# nrf7120_enga_application register map
Vendor: Nordic Semiconductor; Series: nrf71; File version: 1
CPU: CM33 r0p4, little endian, MPU, FPU, 3 interrupt priority bits, 270 interrupts, 4 SAU regions
Registers are 32-bit, read-write, reset 0x0 unless marked. A register's access mark holds for its fields unless they carry their own. Offsets are from the block's base; [hi:lo] are bit positions; {n}, {i} and the like mark numbered series; 'fields as' and 'values as' point back to an identical list; <NAME> marks a mode.

## GLOBAL_COMP_NS — Comparator 0
Base 0x40106000
Same registers: GLOBAL_COMP_S 0x50106000
0x00 TASKS_START wo — Start comparator
  [0] TASKS_START
    1=Trigger task
0x04 TASKS_STOP wo — Stop comparator
  [0] TASKS_STOP
    1=Trigger task
0x08 TASKS_SAMPLE wo — Sample comparator value. This task requires that COMP has been started by the START Task.
  [0] TASKS_SAMPLE
    1=Trigger task
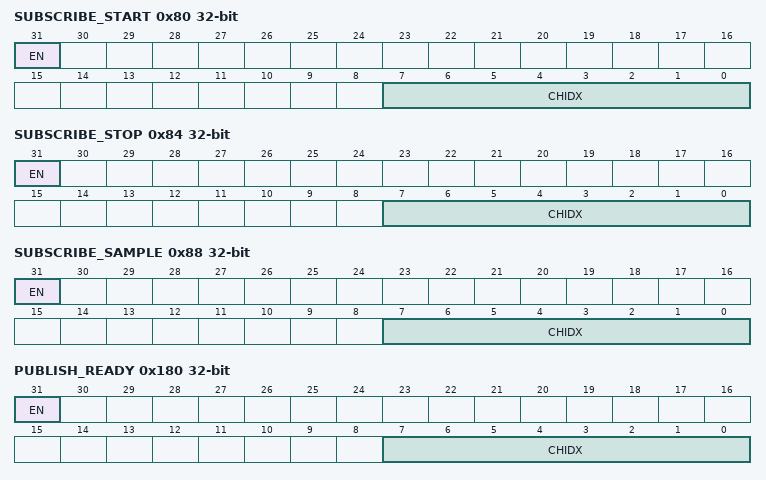
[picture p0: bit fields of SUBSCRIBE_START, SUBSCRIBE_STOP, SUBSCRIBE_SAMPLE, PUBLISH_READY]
0x80 SUBSCRIBE_START — Subscribe configuration for task START
  [31] EN
    0=Disabled (Disable subscription); 1=Enabled (Enable subscription)
  [7:0] CHIDX — DPPI channel that task START will subscribe to
0x84 SUBSCRIBE_STOP — Subscribe configuration for task STOP
  [31] EN
    values as SUBSCRIBE_START.EN
  [7:0] CHIDX — DPPI channel that task STOP will subscribe to
0x88 SUBSCRIBE_SAMPLE — Subscribe configuration for task SAMPLE
  [31] EN
    values as SUBSCRIBE_START.EN
  [7:0] CHIDX — DPPI channel that task SAMPLE will subscribe to
0x100 EVENTS_READY — COMP is ready and output is valid
  [0] EVENTS_READY
    0=NotGenerated (Event not generated); 1=Generated (Event generated)
0x104 EVENTS_DOWN — Downward crossing
  [0] EVENTS_DOWN
    values as EVENTS_READY.EVENTS_READY
0x108 EVENTS_UP — Upward crossing
  [0] EVENTS_UP
    values as EVENTS_READY.EVENTS_READY
0x10C EVENTS_CROSS — Downward or upward crossing
  [0] EVENTS_CROSS
    values as EVENTS_READY.EVENTS_READY
0x180 PUBLISH_READY — Publish configuration for event READY
  [31] EN
    0=Disabled (Disable publishing); 1=Enabled (Enable publishing)
  [7:0] CHIDX — DPPI channel that event READY will publish to
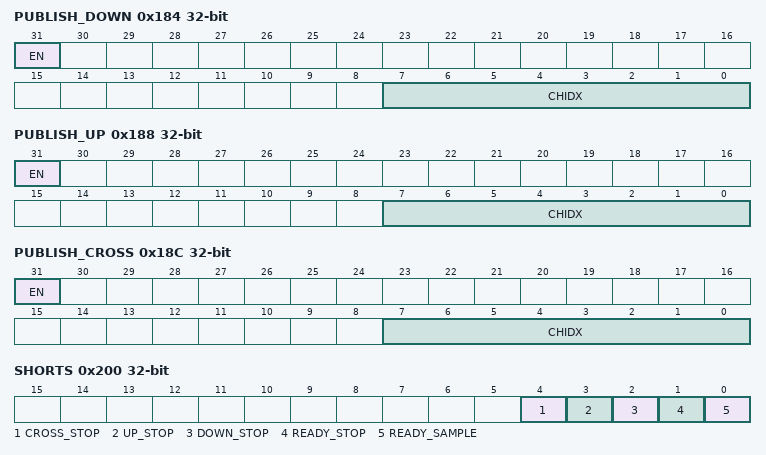
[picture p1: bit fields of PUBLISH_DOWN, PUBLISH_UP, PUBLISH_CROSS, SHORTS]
0x184 PUBLISH_DOWN — Publish configuration for event DOWN
  [31] EN
    values as PUBLISH_READY.EN
  [7:0] CHIDX — DPPI channel that event DOWN will publish to
0x188 PUBLISH_UP — Publish configuration for event UP
  [31] EN
    values as PUBLISH_READY.EN
  [7:0] CHIDX — DPPI channel that event UP will publish to
0x18C PUBLISH_CROSS — Publish configuration for event CROSS
  [31] EN
    values as PUBLISH_READY.EN
  [7:0] CHIDX — DPPI channel that event CROSS will publish to
0x200 SHORTS — Shortcuts between local events and tasks
  [all] fields
    0=Disabled (Disable shortcut); 1=Enabled (Enable shortcut)
  [4] CROSS_STOP — Shortcut between event CROSS and task STOP
  [3] UP_STOP — Shortcut between event UP and task STOP
  [2] DOWN_STOP — Shortcut between event DOWN and task STOP
  [1] READY_STOP — Shortcut between event READY and task STOP
  [0] READY_SAMPLE — Shortcut between event READY and task SAMPLE
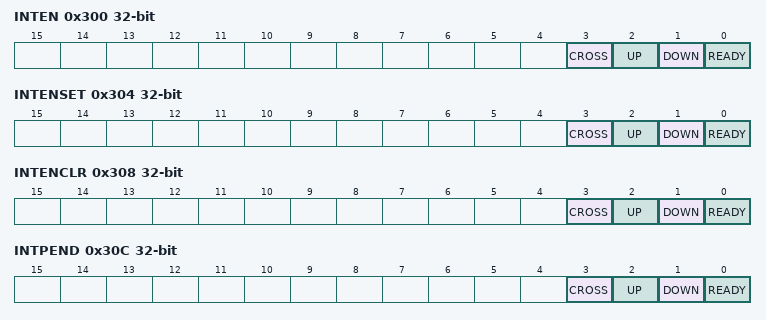
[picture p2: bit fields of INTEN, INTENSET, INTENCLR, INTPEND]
0x300 INTEN — Enable or disable interrupt
  [all] fields
    0=Disabled; 1=Enabled
  [3] CROSS — Enable or disable interrupt for event CROSS
  [2] UP — Enable or disable interrupt for event UP
  [1] DOWN — Enable or disable interrupt for event DOWN
  [0] READY — Enable or disable interrupt for event READY
0x304 INTENSET — Enable interrupt
  [all] fields
    on read: 0=Disabled (Read: Disabled); 1=Enabled (Read: Enabled) | on write: 1=Set (Enable)
  [3] CROSS — Write '1' to enable interrupt for event CROSS
  [2] UP — Write '1' to enable interrupt for event UP
  [1] DOWN — Write '1' to enable interrupt for event DOWN
  [0] READY — Write '1' to enable interrupt for event READY
0x308 INTENCLR — Disable interrupt
  [all] fields
    on read: 0=Disabled (Read: Disabled); 1=Enabled (Read: Enabled) | on write: 1=Clear (Disable)
  [3] CROSS — Write '1' to disable interrupt for event CROSS
  [2] UP — Write '1' to disable interrupt for event UP
  [1] DOWN — Write '1' to disable interrupt for event DOWN
  [0] READY — Write '1' to disable interrupt for event READY
0x30C INTPEND ro — Pending interrupts
  [all] fields
    on read: 0=NotPending (Read: Not pending); 1=Pending (Read: Pending)
  [3] CROSS — Read pending status of interrupt for event CROSS
  [2] UP — Read pending status of interrupt for event UP
  [1] DOWN — Read pending status of interrupt for event DOWN
  [0] READY — Read pending status of interrupt for event READY
0x400 RESULT ro — Compare result
  [0] RESULT — Result of last compare. Decision point SAMPLE task.
    0=Below (Input voltage is below the threshold (VIN+ < VIN-)); 1=Above (Input voltage is above the threshold (VIN+ > VIN-))
0x500 ENABLE — COMP enable
  [1:0] ENABLE — Enable or disable COMP
    0=Disabled; 2=Enabled
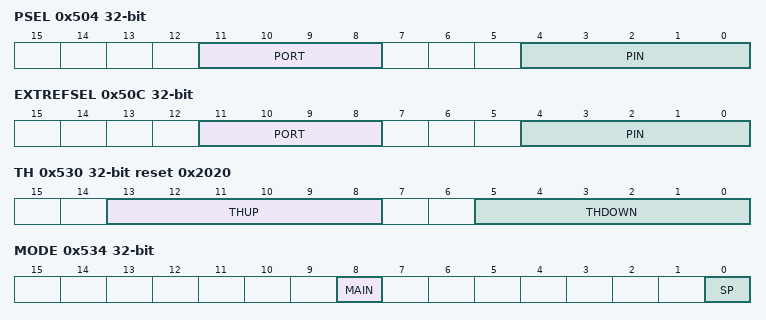
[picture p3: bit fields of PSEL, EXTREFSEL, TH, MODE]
0x504 PSEL — Pin select
  [11:8] PORT — GPIO Port selection
  [4:0] PIN — Analog pin select
0x508 REFSEL reset 0x4 — Reference source select for single-ended mode
  [2:0] REFSEL — Reference select
    0=Int1V2 (VREF = internal 1.2 V reference); 4=VDD (VREF = VDD); 4=AVDDAO1V8 (VREF = internal 1.8 V reference); 5=ARef (VREF = AREF)
0x50C EXTREFSEL — External reference select
  [11:8] PORT — GPIO Port selection
  [4:0] PIN — External analog reference pin select
0x530 TH reset 0x2020 — Threshold configuration for hysteresis unit
  [13:8] THUP — VUP = (THUP+1)/64*VREF
  [5:0] THDOWN — VDOWN = (THDOWN+1)/64*VREF
0x534 MODE — Mode configuration
  [8] MAIN — Main operation modes
    0=SE (Single-ended mode); 1=Differential mode
  [0] SP — Speed and power modes
    0=Low (Low-power mode); 1=High-speed mode
0x538 HYST — Comparator hysteresis enable
  [0] HYST — Comparator hysteresis
    0=NoHyst (Comparator hysteresis disabled); 1=Hyst40mV (Comparator hysteresis enabled)
0x53C ISOURCE — Current source select on analog input
  [1:0] ISOURCE
    0=Off (Current source disabled); 1=Ien2uA5 (Current source enabled (+/- 2.5 uA)); 2=Ien5uA (Current source enabled (+/- 5 uA)); 3=Ien10uA (Current source enabled (+/- 10 uA))
0x540 REFTRIM — Trim internal band gap reference
  [4:0] REFTRIM — Trimming value in 2's complement

## GLOBAL_LPCOMP_NS — Low-power comparator 0
Base 0x40106000; alternate view of GLOBAL_COMP_NS
Same registers: GLOBAL_LPCOMP_S 0x50106000 (alternate view of GLOBAL_COMP_S)
Registers as GLOBAL_COMP_NS, without TH, MODE, ISOURCE, REFTRIM; these are added or differ:
0x08 TASKS_SAMPLE wo — Sample comparator value. This task requires that LPCOMP has been started by the START task.
  [0] TASKS_SAMPLE
    1=Trigger task
0x100 EVENTS_READY — LPCOMP is ready and output is valid
  [0] EVENTS_READY
    0=NotGenerated (Event not generated); 1=Generated (Event generated)
0x400 RESULT ro — Compare result
  [0] RESULT — Result of last compare. Decision point SAMPLE task.
    0=Below (Input voltage is below the reference threshold (VIN+ < VIN-)); 1=Above (Input voltage is above the reference threshold (VIN+ > VIN-))
0x500 ENABLE — Enable LPCOMP
  [1:0] ENABLE — Enable or disable LPCOMP
    0=Disabled; 1=Enabled
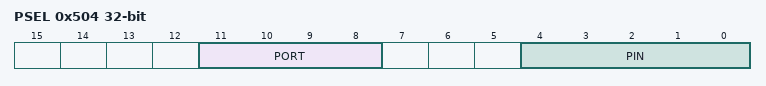
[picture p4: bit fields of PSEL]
0x504 PSEL — Input pin select
  [11:8] PORT — GPIO Port selection
  [4:0] PIN — Analog pin select
0x508 REFSEL reset 0x4 — Reference select
  [3:0] REFSEL
    {v}=Ref{v+1}_8Vdd (VDD * {v+1}/8 selected as reference) (v=0..6); 7=ARef (External analog reference selected); 8=Ref1_16Vdd (VDD * 1/16 selected as reference); 9=Ref3_16Vdd (VDD * 3/16 selected as reference); 10=Ref5_16Vdd (VDD * 5/16 selected as reference); 11=Ref7_16Vdd (VDD * 7/16 selected as reference); 12=Ref9_16Vdd (VDD * 9/16 selected as reference); 13=Ref11_16Vdd (VDD * 11/16 selected as reference); 14=Ref13_16Vdd (VDD * 13/16 selected as reference); 15=Ref15_16Vdd (VDD * 15/16 selected as reference)
0x520 ANADETECT — Analog detect configuration
  [1:0] ANADETECT
    0=Cross (Generate ANADETECT on crossing, both upward crossing and downward crossing); 1=Up (Generate ANADETECT on upward crossing only); 2=Down (Generate ANADETECT on downward crossing only)
0x538 HYST — Comparator hysteresis enable
  [0] HYST
    0=Disabled (Comparator hysteresis disabled); 1=Enabled (Comparator hysteresis enabled)
